AUTOSAR XML (schema 4-0-3)
package /ComponentTypes
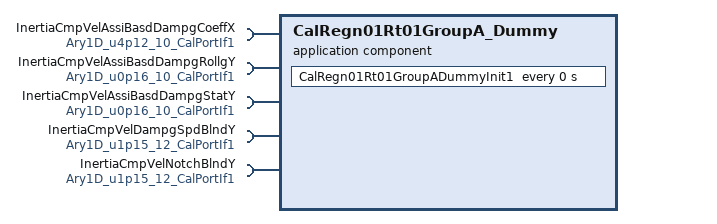
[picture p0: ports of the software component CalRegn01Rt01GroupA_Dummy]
  application sw component type CalRegn01Rt01GroupA_Dummy
    5 x require port:
      InertiaCmpVelAssiBasdDampgCoeffX: parameter-require-com-spec{init-value=[0, 2048, 4096, 6144, 8192, 10240, 12288, 14336, 16384, 18432], parameter=Ary1D}, required-interface=Ary1D_u4p12_10_CalPortIf1
      InertiaCmpVelAssiBasdDampgRollgY: parameter-require-com-spec{init-value=10 x 0, parameter=Ary1D}, required-interface=Ary1D_u0p16_10_CalPortIf1
      InertiaCmpVelAssiBasdDampgStatY: parameter-require-com-spec{init-value=10 x 0, parameter=Ary1D}, required-interface=Ary1D_u0p16_10_CalPortIf1
      InertiaCmpVelDampgSpdBlndY: parameter-require-com-spec{init-value=[32768, 32768, 9830, 6554, 3277, 0, 0, 0, 0, 0, 0, 0], parameter=Ary1D}, required-interface=Ary1D_u1p15_12_CalPortIf1
      InertiaCmpVelNotchBlndY: parameter-require-com-spec{init-value=12 x 0, parameter=Ary1D}, required-interface=Ary1D_u1p15_12_CalPortIf1
    behavior CalRegn01Rt01GroupA_Dummy_InternalBehavior: supports-multiple-instantiation=true
      timing event CalRegn01Rt01GroupA_Dummy_InitEvent: start-on-event=CalRegn01Rt01GroupADummyInit1, period=0
      runnable CalRegn01Rt01GroupADummyInit1
  swc implementation CalRegn01Rt01GroupADummy_Implementation: behavior=CalRegn01Rt01GroupA_Dummy_InternalBehavior
    code-descriptors:
      code Default: artifact-descriptors=autosar-engineering-object={short-label=Default, category=SWSRC}
